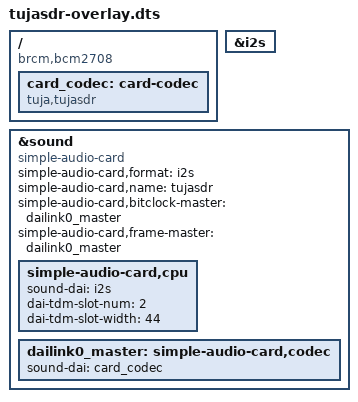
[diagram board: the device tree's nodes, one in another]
/dts-v1/;
/plugin/;

/ {
    compatible = "brcm,bcm2708";

    fragment@0 {
        target = <&i2s>;
        __overlay__ {
            status = "okay";
        };
    };

    fragment@1 {
        target-path = "/";
        __overlay__ {
            card_codec: card-codec {
                #sound-dai-cells = <0>;
                compatible = "tuja,tujasdr";
                status = "okay";
            };
        };
    };

    fragment@2 {
        target = <&sound>;
        __overlay__ {
            compatible = "simple-audio-card";
            simple-audio-card,format = "i2s";
            simple-audio-card,name = "tujasdr";
            simple-audio-card,bitclock-master = <&dailink0_master>;
            simple-audio-card,frame-master = <&dailink0_master>;
            status = "okay";
            simple-audio-card,cpu {
                sound-dai = <&i2s>;
                dai-tdm-slot-num = <2>;
                // We are packing 32 bits in 44 bits
                // This is because of clock reasons
                dai-tdm-slot-width = <44>;
            };
            dailink0_master: simple-audio-card,codec {
                sound-dai = <&card_codec>;
            };
        };
    };
};
